VERSION ""

NS_ :

BS_:

BU_: TTC GatewayPC

BO_ 71 RawSignalThrottlePotiCmd: 2 TTC
 SG_ uint16PotiThrottleCmd : 0|16@1+ (1,0) [0|65535] ""  GatewayPC

BO_ 70 RawSignalVehicleSpeed: 1 TTC
 SG_ uint8VehicleSpeed : 0|8@1+ (0.1,0) [0|25.5] ""  GatewayPC

BO_ 69 RawSignalSteeringVelocityCmd: 2 TTC
 SG_ int16SteeringVelocityCmd : 0|16@1- (1,0) [0|65535] ""  GatewayPC

BO_ 68 RawSignalSteeringVelocity: 2 TTC
 SG_ int16SteeringVelocity : 0|16@1- (0.1,0) [0|0] ""  GatewayPC

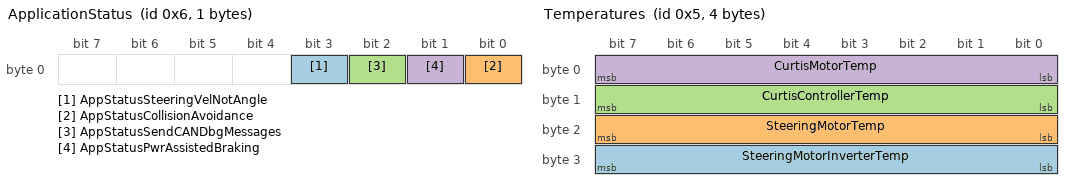
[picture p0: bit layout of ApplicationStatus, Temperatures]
BO_ 6 ApplicationStatus: 1 TTC
 SG_ AppStatusSteeringVelNotAngle : 3|1@1+ (1,0) [0|0] ""  GatewayPC
 SG_ AppStatusCollisionAvoidance : 0|1@1+ (1,0) [0|0] ""  GatewayPC
 SG_ AppStatusSendCANDbgMessages : 2|1@1+ (1,0) [0|0] ""  GatewayPC
 SG_ AppStatusPwrAssistedBraking : 1|1@1+ (1,0) [0|0] ""  GatewayPC

BO_ 5 Temperatures: 4 TTC
 SG_ SteeringMotorInverterTemp : 24|8@1- (1,0) [0|0] "degC"  GatewayPC
 SG_ SteeringMotorTemp : 16|8@1- (1,0) [0|0] "degC"  GatewayPC
 SG_ CurtisControllerTemp : 8|8@1- (1,0) [0|0] "degC"  GatewayPC
 SG_ CurtisMotorTemp : 0|8@1- (1,0) [0|0] "degC"  GatewayPC

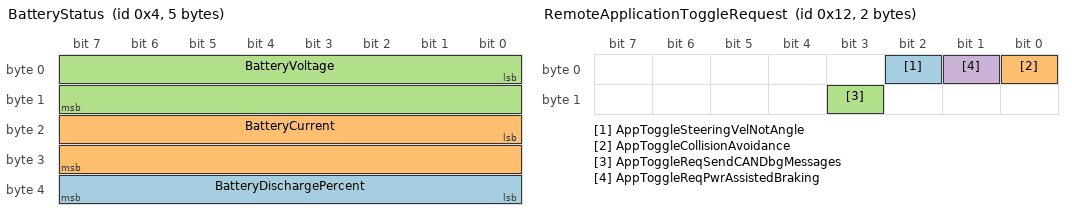
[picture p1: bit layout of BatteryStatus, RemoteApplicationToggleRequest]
BO_ 4 BatteryStatus: 5 TTC
 SG_ BatteryDischargePercent : 32|8@1+ (1,0) [0|0] "%"  GatewayPC
 SG_ BatteryCurrent : 16|16@1+ (0.1,0) [0|0] "A"  GatewayPC
 SG_ BatteryVoltage : 0|16@1+ (0.01,0) [0|0] "V"  GatewayPC

BO_ 18 RemoteApplicationToggleRequest: 2 GatewayPC
 SG_ AppToggleSteeringVelNotAngle : 2|1@1+ (1,0) [0|0] ""  TTC
 SG_ AppToggleCollisionAvoidance : 0|1@1+ (1,0) [0|0] ""  TTC
 SG_ AppToggleReqSendCANDbgMessages : 11|1@1+ (1,0) [0|0] ""  TTC
 SG_ AppToggleReqPwrAssistedBraking : 1|1@1+ (1,0) [0|0] ""  TTC

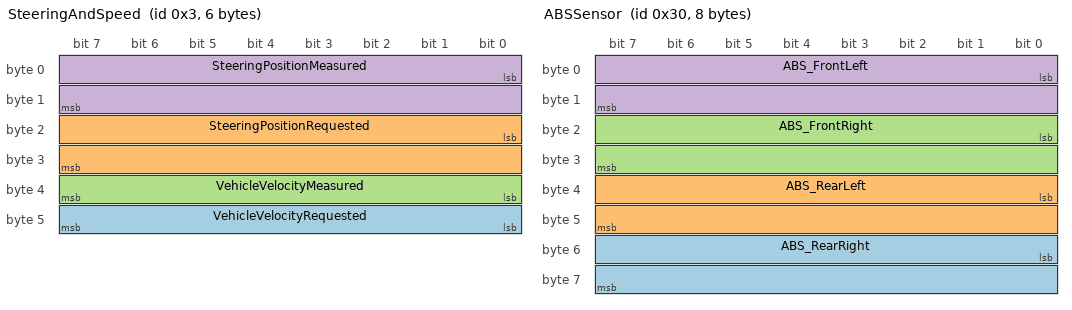
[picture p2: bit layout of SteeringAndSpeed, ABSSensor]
BO_ 3 SteeringAndSpeed: 6 TTC
 SG_ VehicleVelocityRequested : 40|8@1- (1,0) [-128|127] "%"  GatewayPC
 SG_ SteeringPositionRequested : 16|16@1- (0.005,0) [-163.84|163.835] "deg"  GatewayPC
 SG_ VehicleVelocityMeasured : 32|8@1- (0.1,0) [-12.8|12.7] "m/s"  GatewayPC
 SG_ SteeringPositionMeasured : 0|16@1- (0.005,0) [-163.84|163.835] "deg"  GatewayPC

BO_ 48 ABSSensor: 8 TTC
 SG_ ABS_RearRight : 48|16@1+ (1,0) [0|0] "Hz"  GatewayPC
 SG_ ABS_RearLeft : 32|16@1+ (1,0) [0|0] "Hz"  GatewayPC
 SG_ ABS_FrontRight : 16|16@1+ (1,0) [0|0] "Hz"  GatewayPC
 SG_ ABS_FrontLeft : 0|16@1+ (1,0) [0|0] "Hz"  GatewayPC

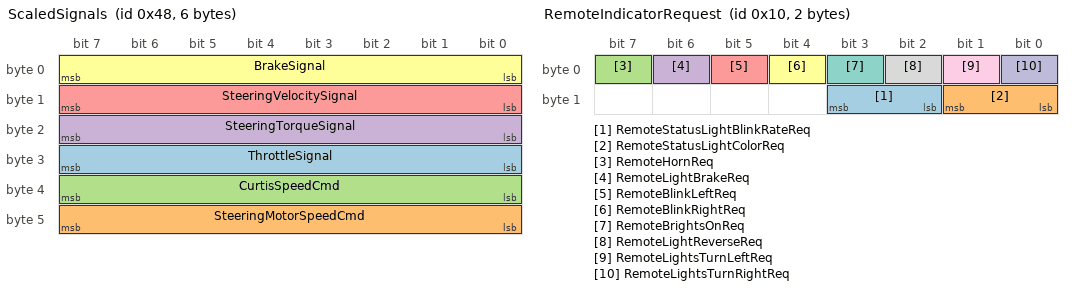
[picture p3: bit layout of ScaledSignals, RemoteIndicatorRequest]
BO_ 72 ScaledSignals: 6 TTC
 SG_ ThrottleSignal : 24|8@1+ (1,0) [0|255] ""  GatewayPC
 SG_ SteeringMotorSpeedCmd : 40|8@1- (1,0) [0|0] "%"  GatewayPC
 SG_ CurtisSpeedCmd : 32|8@1+ (1,0) [0|0] ""  GatewayPC
 SG_ SteeringTorqueSignal : 16|8@1- (1,0) [0|0] ""  GatewayPC
 SG_ SteeringVelocitySignal : 8|8@1- (1,0) [-128|127] "%"  GatewayPC
 SG_ BrakeSignal : 0|8@1+ (1,0) [0|0] "%"  GatewayPC

BO_ 67 RawSignalSteeringPosition: 4 TTC
 SG_ uint16EncoderRawValueB : 16|16@1+ (1,0) [0|0] ""  GatewayPC
 SG_ uint16EncoderRawValueA : 0|16@1+ (1,0) [0|0] ""  GatewayPC

BO_ 66 RawSignalSteeringForce: 8 TTC
 SG_ uint32SignalSteeringForceB : 32|32@1+ (1,0) [0|0] ""  GatewayPC
 SG_ uint32SignalSteeringForceA : 0|32@1+ (1,0) [0|0] ""  GatewayPC

BO_ 65 RawSignalBrake: 8 TTC
 SG_ uint32SignalBrakeB : 32|32@1+ (1,0) [0|0] ""  GatewayPC
 SG_ uint32SignalBrakeA : 0|32@1+ (1,0) [0|0] ""  GatewayPC

BO_ 64 RawSignalThrottle: 8 TTC
 SG_ uint32SignalThrottleB : 32|32@1+ (1,0) [0|0] ""  GatewayPC
 SG_ uint32SignalThrottleA : 0|32@1+ (1,0) [0|0] ""  GatewayPC

BO_ 16 RemoteIndicatorRequest: 2 GatewayPC
 SG_ RemoteStatusLightBlinkRateReq : 10|2@1+ (1,0) [0|0] ""  TTC
 SG_ RemoteStatusLightColorReq : 8|2@1+ (1,0) [0|0] ""  TTC
 SG_ RemoteHornReq : 7|1@1+ (1,0) [0|0] ""  TTC
 SG_ RemoteLightBrakeReq : 6|1@1+ (1,0) [0|0] ""  TTC
 SG_ RemoteBlinkLeftReq : 5|1@1+ (1,0) [0|0] ""  TTC
 SG_ RemoteBlinkRightReq : 4|1@1+ (1,0) [0|0] ""  TTC
 SG_ RemoteBrightsOnReq : 3|1@1+ (1,0) [0|0] ""  TTC
 SG_ RemoteLightReverseReq : 2|1@1+ (1,0) [0|0] ""  TTC
 SG_ RemoteLightsTurnLeftReq : 1|1@1+ (1,0) [0|0] ""  TTC
 SG_ RemoteLightsTurnRightReq : 0|1@1+ (1,0) [0|0] ""  TTC

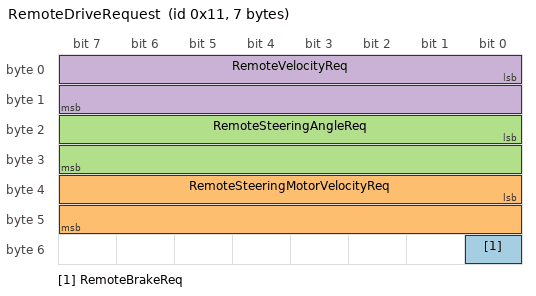
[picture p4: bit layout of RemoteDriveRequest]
BO_ 17 RemoteDriveRequest: 7 GatewayPC
 SG_ RemoteBrakeReq : 48|1@1+ (1,0) [0|0] ""  TTC
 SG_ RemoteSteeringMotorVelocityReq : 32|16@1- (0.01,0) [-327.68|327.67] "%" Vector__XXX
 SG_ RemoteSteeringAngleReq : 16|16@1- (0.01,0) [-327.68|327.67] "deg"  TTC
 SG_ RemoteVelocityReq : 0|16@1- (0.01,0) [-327.68|327.67] "%"  TTC

BO_ 2 GeneralVehicleStatus: 8 TTC
 SG_ SteeringPositionEndSwitchReached : 62|1@1+ (1,0) [0|0] ""  GatewayPC
 SG_ RequestSteeringMotorInhibit : 58|1@1+ (1,0) [0|0] ""  GatewayPC
 SG_ CollisionAvoidance_Stop : 61|1@1+ (1,0) [0|0] ""  GatewayPC
 SG_ CollisionAvoidance_Slowdown : 60|1@1+ (1,0) [0|0] ""  GatewayPC
 SG_ Signal12Switch : 39|1@1+ (1,0) [0|0] ""  GatewayPC
 SG_ RequestZeroThrottle : 56|1@1+ (1,0) [0|0] ""  GatewayPC
 SG_ RequestBrake : 57|1@1+ (1,0) [0|0] ""  GatewayPC
 SG_ SignalBrightsOn : 35|1@1+ (1,0) [0|0] ""  GatewayPC
 SG_ SignalRightTurn : 32|1@1+ (1,0) [0|0] ""  GatewayPC
 SG_ SignalLeftTurn : 33|1@1+ (1,0) [0|0] ""  GatewayPC
 SG_ SignalHorn : 38|1@1+ (1,0) [0|0] ""  GatewayPC
 SG_ SignalHazardLights : 37|1@1+ (1,0) [0|0] ""  GatewayPC
 SG_ SignalDirectionReverse : 34|1@1+ (1,0) [0|0] ""  GatewayPC
 SG_ GlobalManSigMagBrake : 30|1@1+ (1,0) [0|0] ""  GatewayPC
 SG_ GlobalCurtisSigMagBrake : 31|1@1+ (1,0) [0|0] ""  GatewayPC
 SG_ SignalBrakeSwitch : 29|1@1+ (1,0) [0|0] ""  GatewayPC
 SG_ SignalSeatSwitch : 28|1@1+ (1,0) [0|0] ""  GatewayPC
 SG_ EStopStatus : 3|1@1+ (1,0) [0|0] ""  GatewayPC
 SG_ SelectedApplication : 4|4@1+ (1,0) [0|0] ""  GatewayPC
 SG_ SelectedOpMode : 8|4@1+ (1,0) [0|0] ""  GatewayPC
 SG_ ActiveOpMode : 12|4@1+ (1,0) [0|0] ""  GatewayPC
 SG_ ButtonBlue : 0|1@1+ (1,0) [0|0] ""  GatewayPC
 SG_ ButtonYellow : 1|1@1+ (1,0) [0|0] ""  GatewayPC
 SG_ ButtonGreen : 2|1@1+ (1,0) [0|0] ""  GatewayPC

CM_ BU_ TTC "TTC580";
CM_ BU_ GatewayPC "Linux";
CM_ SG_ 71 uint16PotiThrottleCmd "Raw signal sent to the throttle-poti input of the curtis motor";
CM_ SG_ 70 uint8VehicleSpeed "Raw vehicle speed value as measured by the encoder";
CM_ SG_ 69 int16SteeringVelocityCmd "Raw velocity signal output sent to the steering motor";
CM_ SG_ 68 int16SteeringVelocity "Raw feedback value of the steering motor velocity";
CM_ SG_ 3 VehicleVelocityRequested "requested vehicle velocity";
CM_ SG_ 3 SteeringPositionRequested "Scaled requested steering position";
CM_ SG_ 3 VehicleVelocityMeasured "measured vehicle velocity";
CM_ SG_ 3 SteeringPositionMeasured "Scaled steering position as measured by the encoders";
CM_ SG_ 48 ABS_RearRight "Frequency of the rear right wheel encoder reading";
CM_ SG_ 48 ABS_RearLeft "Frequency of the rear left wheel encoder reading";
CM_ SG_ 48 ABS_FrontRight "Frequency of the front right wheel encoder reading";
CM_ SG_ 48 ABS_FrontLeft "Frequency of the front left wheel encoder reading";
CM_ SG_ 72 ThrottleSignal "Scaled throttle signal received from the handlebar sensor";
CM_ SG_ 72 SteeringMotorSpeedCmd "Scaled speed command value sent to the steering motor";
CM_ SG_ 72 CurtisSpeedCmd "Scaled speed command sent to the curtis motor";
CM_ SG_ 72 SteeringTorqueSignal "Scaled steering torque signal as measured by the force-sensors";
CM_ SG_ 72 SteeringVelocitySignal "Scaled steering velocity signal as received from the steering motor";
CM_ SG_ 72 BrakeSignal "Scaled braking signal from handlebar";
CM_ SG_ 67 uint16EncoderRawValueB "Raw signal of the steering position encoder B";
CM_ SG_ 67 uint16EncoderRawValueA "Raw signal of the steering position encoder A";
CM_ SG_ 66 uint32SignalSteeringForceB "Raw signal of the steering force sensor B";
CM_ SG_ 66 uint32SignalSteeringForceA "Raw signal of the steering force sensor A";
CM_ SG_ 65 uint32SignalBrakeB "Raw signal of the brake sensor B";
CM_ SG_ 65 uint32SignalBrakeA "Raw signal of the brake sensor A";
CM_ SG_ 64 uint32SignalThrottleB "Raw throttle signals received from the handlebar sensor B";
CM_ SG_ 64 uint32SignalThrottleA "Raw throttle signals received from the handlebar sensor A";
CM_ SG_ 16 RemoteStatusLightBlinkRateReq "Request blink rate of status lights  (the value is multiplied with 250ms: 0=static, 1=4Hz, 2=2Hz, etc.)";
CM_ SG_ 16 RemoteStatusLightColorReq "Request color of status lights (0=off, 1=green, 2=yellow, 3=red)";
CM_ SG_ 16 RemoteHornReq "Request to turn accoustic horn on";
CM_ SG_ 16 RemoteLightBrakeReq "Request to turn brake lights on";
CM_ SG_ 16 RemoteBlinkLeftReq "Request to turn 'blink left' light on";
CM_ SG_ 16 RemoteBlinkRightReq "Request to turn 'blink right' light on";
CM_ SG_ 16 RemoteBrightsOnReq "Request to turn brights on";
CM_ SG_ 16 RemoteLightReverseReq "Request to turn reverse lights on";
CM_ SG_ 16 RemoteLightsTurnLeftReq "Request to turn 'turn left' lights on";
CM_ SG_ 16 RemoteLightsTurnRightReq "Request to turn 'turn right' lights on";
CM_ SG_ 17 RemoteBrakeReq "Request vehicle to brake";
CM_ SG_ 17 RemoteSteeringMotorVelocityReq "Requested steering motor velocity";
CM_ SG_ 17 RemoteSteeringAngleReq "Requested steering angle (0=center, +100=full right, -100=full left)";
CM_ SG_ 17 RemoteVelocityReq "Requested driving velocity (positive values result in drive forward)";
CM_ SG_ 2 RequestSteeringMotorInhibit "TTC internal software signal reflecting whether the steering motor is inhibited due to an internal reason";
CM_ SG_ 2 CollisionAvoidance_Stop "Stop request due to the collision avoidance function";
CM_ SG_ 2 CollisionAvoidance_Slowdown "Slowdown request due to the collision avoidance function";
CM_ SG_ 2 Signal12Switch "State of the '1-2'-switch";
CM_ SG_ 2 RequestZeroThrottle "TTC internal software signal reflecting whether the throttle is set to zero due to an internal reasion";
CM_ SG_ 2 RequestBrake "TTC internal software signal reflecting whether braking is requested due to an internal reason";
CM_ SG_ 2 SignalBrightsOn "State of the 'brights on'-switch";
CM_ SG_ 2 SignalRightTurn "TBD";
CM_ SG_ 2 SignalLeftTurn "TBD";
CM_ SG_ 2 SignalHorn "State of the 'horn on'-button";
CM_ SG_ 2 SignalHazardLights "State of the 'hazard lights on'-switch";
CM_ SG_ 2 SignalDirectionReverse "State of the 'direction reverse'-switch";
CM_ SG_ 2 SignalBrakeSwitch "State of the brake-switch integrated into the handlebar";
CM_ SG_ 2 SignalSeatSwitch "State of the 'seat empty'-switch";
CM_ SG_ 2 EStopStatus "State of the emergency button(s)";
CM_ SG_ 2 SelectedApplication "Currently selected 'Application'";
CM_ SG_ 2 SelectedOpMode "Currently selected 'OpMode'";
CM_ SG_ 2 ActiveOpMode "Currently active 'OpMode'";
CM_ SG_ 2 ButtonBlue "State of the blue button in the cockpit";
CM_ SG_ 2 ButtonYellow "State of the yellow button in the cockpit";
CM_ SG_ 2 ButtonGreen "State of the green button in the cockpit";
